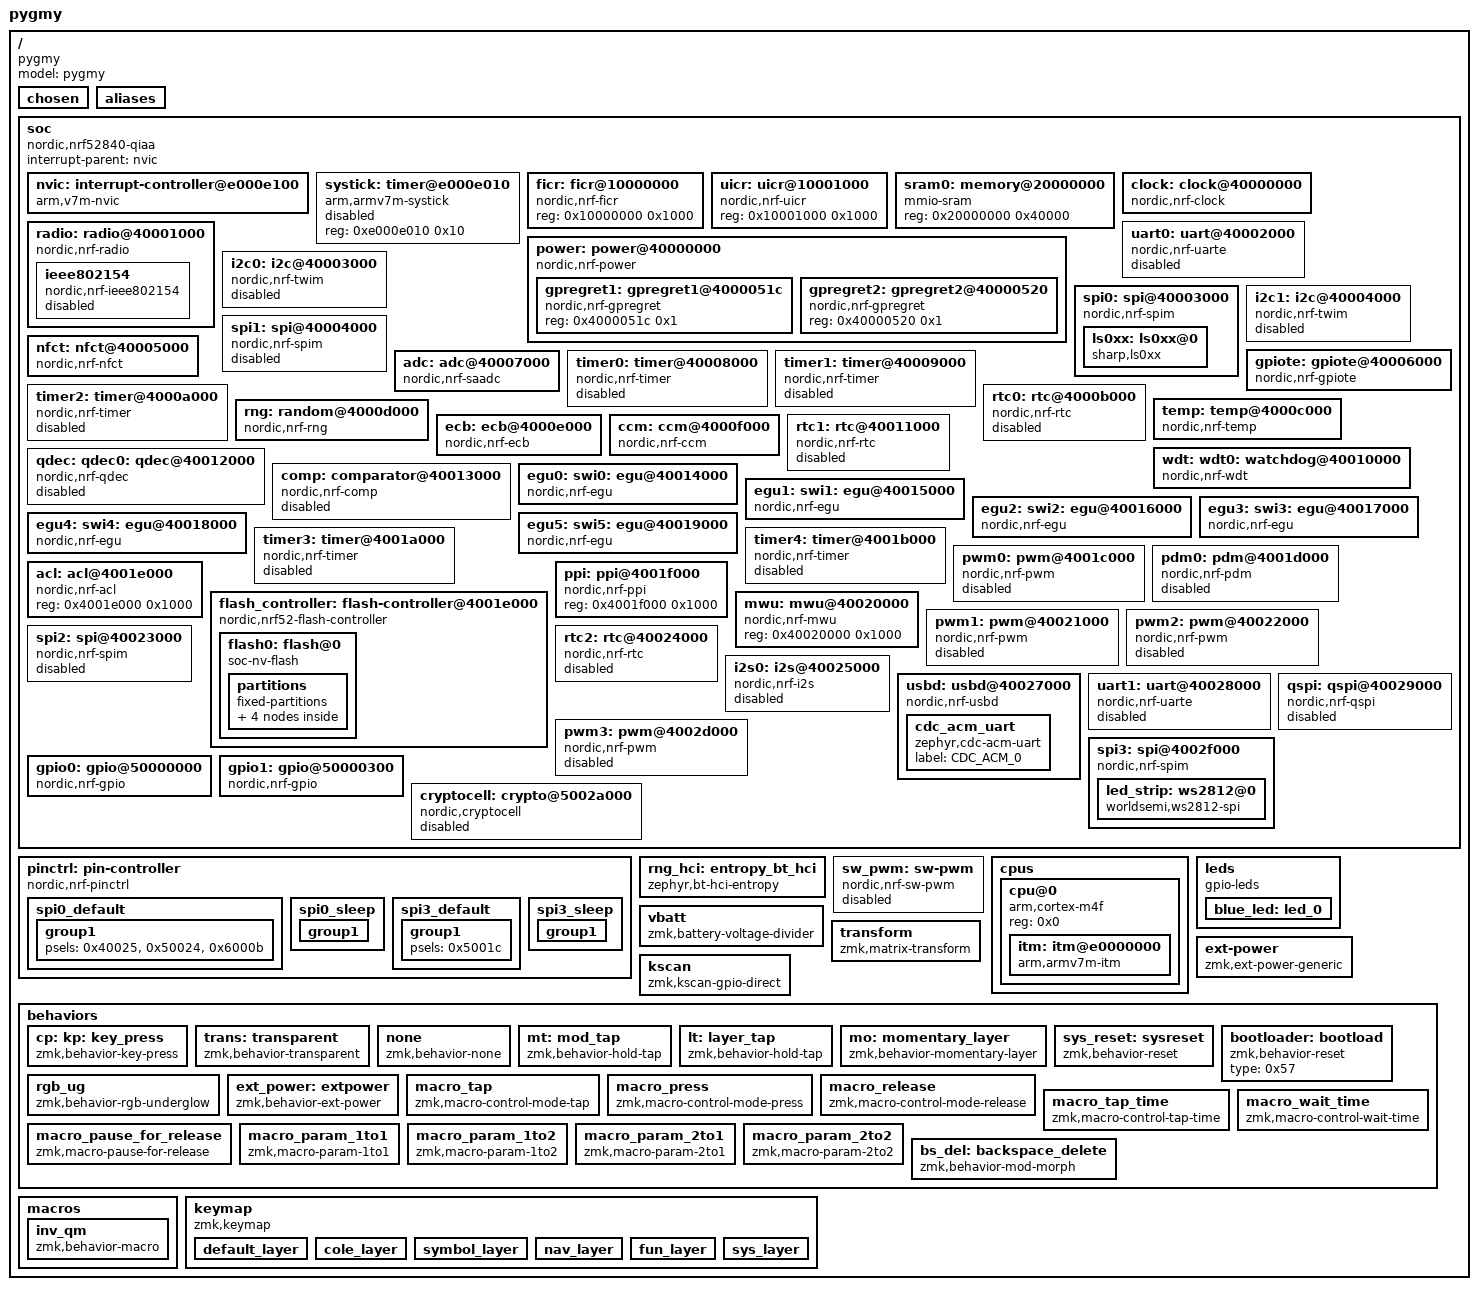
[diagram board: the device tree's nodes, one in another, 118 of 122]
/dts-v1/;

/ {
	#address-cells = < 0x1 >;
	#size-cells = < 0x1 >;
	model = "pygmy";
	compatible = "pygmy";
	chosen {
		zephyr,entropy = &rng;
		zephyr,flash-controller = &flash_controller;
		zephyr,code-partition = &code_partition;
		zephyr,sram = &sram0;
		zephyr,flash = &flash0;
		zephyr,display = &ls0xx;
		zmk,kscan = &kscan;
		zmk,matrix_transform = &transform;
		zmk,battery = &vbatt;
		zephyr,console = &cdc_acm_uart;
		zmk,underglow = &led_strip;
	};
	aliases {
	};
	soc {
		#address-cells = < 0x1 >;
		#size-cells = < 0x1 >;
		compatible = "nordic,nrf52840-qiaa", "nordic,nrf52840", "nordic,nrf52", "simple-bus";
		interrupt-parent = < &nvic >;
		ranges;
		nvic: interrupt-controller@e000e100 {
			#address-cells = < 0x1 >;
			compatible = "arm,v7m-nvic";
			reg = < 0xe000e100 0xc00 >;
			interrupt-controller;
			#interrupt-cells = < 0x2 >;
			arm,num-irq-priority-bits = < 0x3 >;
			phandle = < 0x1 >;
		};
		systick: timer@e000e010 {
			compatible = "arm,armv7m-systick";
			reg = < 0xe000e010 0x10 >;
			status = "disabled";
		};
		ficr: ficr@10000000 {
			compatible = "nordic,nrf-ficr";
			reg = < 0x10000000 0x1000 >;
			status = "okay";
		};
		uicr: uicr@10001000 {
			compatible = "nordic,nrf-uicr";
			reg = < 0x10001000 0x1000 >;
			status = "okay";
		};
		sram0: memory@20000000 {
			compatible = "mmio-sram";
			reg = < 0x20000000 0x40000 >;
		};
		clock: clock@40000000 {
			compatible = "nordic,nrf-clock";
			reg = < 0x40000000 0x1000 >;
			interrupts = < 0x0 0x1 >;
			status = "okay";
		};
		power: power@40000000 {
			compatible = "nordic,nrf-power";
			reg = < 0x40000000 0x1000 >;
			interrupts = < 0x0 0x1 >;
			status = "okay";
			#address-cells = < 0x1 >;
			#size-cells = < 0x1 >;
			gpregret1: gpregret1@4000051c {
				#address-cells = < 0x1 >;
				#size-cells = < 0x1 >;
				compatible = "nordic,nrf-gpregret";
				reg = < 0x4000051c 0x1 >;
				status = "okay";
			};
			gpregret2: gpregret2@40000520 {
				#address-cells = < 0x1 >;
				#size-cells = < 0x1 >;
				compatible = "nordic,nrf-gpregret";
				reg = < 0x40000520 0x1 >;
				status = "okay";
			};
		};
		radio: radio@40001000 {
			compatible = "nordic,nrf-radio";
			reg = < 0x40001000 0x1000 >;
			interrupts = < 0x1 0x1 >;
			status = "okay";
			ieee802154-supported;
			ble-2mbps-supported;
			ble-coded-phy-supported;
			tx-high-power-supported;
			ieee802154: ieee802154 {
				compatible = "nordic,nrf-ieee802154";
				status = "disabled";
			};
		};
		uart0: uart@40002000 {
			compatible = "nordic,nrf-uarte";
			reg = < 0x40002000 0x1000 >;
			interrupts = < 0x2 0x1 >;
			status = "disabled";
		};
		i2c0: i2c@40003000 {
			compatible = "nordic,nrf-twim";
			#address-cells = < 0x1 >;
			#size-cells = < 0x0 >;
			reg = < 0x40003000 0x1000 >;
			clock-frequency = < 0x186a0 >;
			interrupts = < 0x3 0x1 >;
			easydma-maxcnt-bits = < 0x10 >;
			status = "disabled";
		};
		spi0: spi@40003000 {
			compatible = "nordic,nrf-spim";
			#address-cells = < 0x1 >;
			#size-cells = < 0x0 >;
			reg = < 0x40003000 0x1000 >;
			interrupts = < 0x3 0x1 >;
			max-frequency = < 0x7a1200 >;
			easydma-maxcnt-bits = < 0x10 >;
			status = "okay";
			pinctrl-0 = < &spi0_default >;
			pinctrl-1 = < &spi0_default >;
			pinctrl-names = "default", "sleep";
			cs-gpios = < &gpio0 0x1e 0x0 >;
			ls0xx: ls0xx@0 {
				compatible = "sharp,ls0xx";
				spi-max-frequency = < 0x1e8480 >;
				reg = < 0x0 >;
				width = < 0x90 >;
				height = < 0xa8 >;
			};
		};
		i2c1: i2c@40004000 {
			compatible = "nordic,nrf-twim";
			#address-cells = < 0x1 >;
			#size-cells = < 0x0 >;
			reg = < 0x40004000 0x1000 >;
			clock-frequency = < 0x186a0 >;
			interrupts = < 0x4 0x1 >;
			easydma-maxcnt-bits = < 0x10 >;
			status = "disabled";
		};
		spi1: spi@40004000 {
			compatible = "nordic,nrf-spim";
			#address-cells = < 0x1 >;
			#size-cells = < 0x0 >;
			reg = < 0x40004000 0x1000 >;
			interrupts = < 0x4 0x1 >;
			max-frequency = < 0x7a1200 >;
			easydma-maxcnt-bits = < 0x10 >;
			status = "disabled";
		};
		nfct: nfct@40005000 {
			compatible = "nordic,nrf-nfct";
			reg = < 0x40005000 0x1000 >;
			interrupts = < 0x5 0x1 >;
			status = "okay";
		};
		gpiote: gpiote@40006000 {
			compatible = "nordic,nrf-gpiote";
			reg = < 0x40006000 0x1000 >;
			interrupts = < 0x6 0x5 >;
			status = "okay";
		};
		adc: adc@40007000 {
			compatible = "nordic,nrf-saadc";
			reg = < 0x40007000 0x1000 >;
			interrupts = < 0x7 0x1 >;
			status = "okay";
			#io-channel-cells = < 0x1 >;
			phandle = < 0x7 >;
		};
		timer0: timer@40008000 {
			compatible = "nordic,nrf-timer";
			status = "disabled";
			reg = < 0x40008000 0x1000 >;
			cc-num = < 0x4 >;
			max-bit-width = < 0x20 >;
			interrupts = < 0x8 0x1 >;
			prescaler = < 0x0 >;
		};
		timer1: timer@40009000 {
			compatible = "nordic,nrf-timer";
			status = "disabled";
			reg = < 0x40009000 0x1000 >;
			cc-num = < 0x4 >;
			max-bit-width = < 0x20 >;
			interrupts = < 0x9 0x1 >;
			prescaler = < 0x0 >;
			phandle = < 0x6 >;
		};
		timer2: timer@4000a000 {
			compatible = "nordic,nrf-timer";
			status = "disabled";
			reg = < 0x4000a000 0x1000 >;
			cc-num = < 0x4 >;
			max-bit-width = < 0x20 >;
			interrupts = < 0xa 0x1 >;
			prescaler = < 0x0 >;
		};
		rtc0: rtc@4000b000 {
			compatible = "nordic,nrf-rtc";
			reg = < 0x4000b000 0x1000 >;
			cc-num = < 0x3 >;
			interrupts = < 0xb 0x1 >;
			status = "disabled";
			clock-frequency = < 0x8000 >;
			prescaler = < 0x1 >;
		};
		temp: temp@4000c000 {
			compatible = "nordic,nrf-temp";
			reg = < 0x4000c000 0x1000 >;
			interrupts = < 0xc 0x1 >;
			status = "okay";
		};
		rng: random@4000d000 {
			compatible = "nordic,nrf-rng";
			reg = < 0x4000d000 0x1000 >;
			interrupts = < 0xd 0x1 >;
			status = "okay";
		};
		ecb: ecb@4000e000 {
			compatible = "nordic,nrf-ecb";
			reg = < 0x4000e000 0x1000 >;
			interrupts = < 0xe 0x1 >;
			status = "okay";
		};
		ccm: ccm@4000f000 {
			compatible = "nordic,nrf-ccm";
			reg = < 0x4000f000 0x1000 >;
			interrupts = < 0xf 0x1 >;
			length-field-length-8-bits;
			status = "okay";
		};
		wdt: wdt0: watchdog@40010000 {
			compatible = "nordic,nrf-wdt";
			reg = < 0x40010000 0x1000 >;
			interrupts = < 0x10 0x1 >;
			status = "okay";
		};
		rtc1: rtc@40011000 {
			compatible = "nordic,nrf-rtc";
			reg = < 0x40011000 0x1000 >;
			cc-num = < 0x4 >;
			interrupts = < 0x11 0x1 >;
			status = "disabled";
			clock-frequency = < 0x8000 >;
			prescaler = < 0x1 >;
		};
		qdec: qdec0: qdec@40012000 {
			compatible = "nordic,nrf-qdec";
			reg = < 0x40012000 0x1000 >;
			interrupts = < 0x12 0x1 >;
			status = "disabled";
		};
		comp: comparator@40013000 {
			compatible = "nordic,nrf-comp";
			reg = < 0x40013000 0x1000 >;
			interrupts = < 0x13 0x1 >;
			status = "disabled";
			#io-channel-cells = < 0x1 >;
		};
		egu0: swi0: egu@40014000 {
			compatible = "nordic,nrf-egu", "nordic,nrf-swi";
			reg = < 0x40014000 0x1000 >;
			interrupts = < 0x14 0x1 >;
			status = "okay";
		};
		egu1: swi1: egu@40015000 {
			compatible = "nordic,nrf-egu", "nordic,nrf-swi";
			reg = < 0x40015000 0x1000 >;
			interrupts = < 0x15 0x1 >;
			status = "okay";
		};
		egu2: swi2: egu@40016000 {
			compatible = "nordic,nrf-egu", "nordic,nrf-swi";
			reg = < 0x40016000 0x1000 >;
			interrupts = < 0x16 0x1 >;
			status = "okay";
		};
		egu3: swi3: egu@40017000 {
			compatible = "nordic,nrf-egu", "nordic,nrf-swi";
			reg = < 0x40017000 0x1000 >;
			interrupts = < 0x17 0x1 >;
			status = "okay";
		};
		egu4: swi4: egu@40018000 {
			compatible = "nordic,nrf-egu", "nordic,nrf-swi";
			reg = < 0x40018000 0x1000 >;
			interrupts = < 0x18 0x1 >;
			status = "okay";
		};
		egu5: swi5: egu@40019000 {
			compatible = "nordic,nrf-egu", "nordic,nrf-swi";
			reg = < 0x40019000 0x1000 >;
			interrupts = < 0x19 0x1 >;
			status = "okay";
		};
		timer3: timer@4001a000 {
			compatible = "nordic,nrf-timer";
			status = "disabled";
			reg = < 0x4001a000 0x1000 >;
			cc-num = < 0x6 >;
			max-bit-width = < 0x20 >;
			interrupts = < 0x1a 0x1 >;
			prescaler = < 0x0 >;
		};
		timer4: timer@4001b000 {
			compatible = "nordic,nrf-timer";
			status = "disabled";
			reg = < 0x4001b000 0x1000 >;
			cc-num = < 0x6 >;
			max-bit-width = < 0x20 >;
			interrupts = < 0x1b 0x1 >;
			prescaler = < 0x0 >;
		};
		pwm0: pwm@4001c000 {
			compatible = "nordic,nrf-pwm";
			reg = < 0x4001c000 0x1000 >;
			interrupts = < 0x1c 0x1 >;
			status = "disabled";
			#pwm-cells = < 0x3 >;
		};
		pdm0: pdm@4001d000 {
			compatible = "nordic,nrf-pdm";
			reg = < 0x4001d000 0x1000 >;
			interrupts = < 0x1d 0x1 >;
			status = "disabled";
		};
		acl: acl@4001e000 {
			compatible = "nordic,nrf-acl";
			reg = < 0x4001e000 0x1000 >;
			status = "okay";
		};
		flash_controller: flash-controller@4001e000 {
			compatible = "nordic,nrf52-flash-controller";
			reg = < 0x4001e000 0x1000 >;
			partial-erase;
			#address-cells = < 0x1 >;
			#size-cells = < 0x1 >;
			flash0: flash@0 {
				compatible = "soc-nv-flash";
				erase-block-size = < 0x1000 >;
				write-block-size = < 0x4 >;
				reg = < 0x0 0x100000 >;
				partitions {
					compatible = "fixed-partitions";
					#address-cells = < 0x1 >;
					#size-cells = < 0x1 >;
					sd_partition: partition@0 {
						reg = < 0x0 0x1000 >;
					};
					code_partition: partition@1000 {
						reg = < 0x1000 0xd3000 >;
					};
					storage_partition: partition@d4000 {
						reg = < 0xd4000 0x20000 >;
					};
					boot_partition: partition@f4000 {
						reg = < 0xf4000 0xc000 >;
					};
				};
			};
		};
		ppi: ppi@4001f000 {
			compatible = "nordic,nrf-ppi";
			reg = < 0x4001f000 0x1000 >;
			status = "okay";
		};
		mwu: mwu@40020000 {
			compatible = "nordic,nrf-mwu";
			reg = < 0x40020000 0x1000 >;
			status = "okay";
		};
		pwm1: pwm@40021000 {
			compatible = "nordic,nrf-pwm";
			reg = < 0x40021000 0x1000 >;
			interrupts = < 0x21 0x1 >;
			status = "disabled";
			#pwm-cells = < 0x3 >;
		};
		pwm2: pwm@40022000 {
			compatible = "nordic,nrf-pwm";
			reg = < 0x40022000 0x1000 >;
			interrupts = < 0x22 0x1 >;
			status = "disabled";
			#pwm-cells = < 0x3 >;
		};
		spi2: spi@40023000 {
			compatible = "nordic,nrf-spim";
			#address-cells = < 0x1 >;
			#size-cells = < 0x0 >;
			reg = < 0x40023000 0x1000 >;
			interrupts = < 0x23 0x1 >;
			max-frequency = < 0x7a1200 >;
			easydma-maxcnt-bits = < 0x10 >;
			status = "disabled";
		};
		rtc2: rtc@40024000 {
			compatible = "nordic,nrf-rtc";
			reg = < 0x40024000 0x1000 >;
			cc-num = < 0x4 >;
			interrupts = < 0x24 0x1 >;
			status = "disabled";
			clock-frequency = < 0x8000 >;
			prescaler = < 0x1 >;
		};
		i2s0: i2s@40025000 {
			compatible = "nordic,nrf-i2s";
			#address-cells = < 0x1 >;
			#size-cells = < 0x0 >;
			reg = < 0x40025000 0x1000 >;
			interrupts = < 0x25 0x1 >;
			status = "disabled";
		};
		usbd: usbd@40027000 {
			compatible = "nordic,nrf-usbd";
			reg = < 0x40027000 0x1000 >;
			interrupts = < 0x27 0x1 >;
			num-bidir-endpoints = < 0x1 >;
			num-in-endpoints = < 0x7 >;
			num-out-endpoints = < 0x7 >;
			num-isoin-endpoints = < 0x1 >;
			num-isoout-endpoints = < 0x1 >;
			status = "okay";
			cdc_acm_uart: cdc_acm_uart {
				compatible = "zephyr,cdc-acm-uart";
				label = "CDC_ACM_0";
			};
		};
		uart1: uart@40028000 {
			compatible = "nordic,nrf-uarte";
			reg = < 0x40028000 0x1000 >;
			interrupts = < 0x28 0x1 >;
			status = "disabled";
		};
		qspi: qspi@40029000 {
			compatible = "nordic,nrf-qspi";
			#address-cells = < 0x1 >;
			#size-cells = < 0x0 >;
			reg = < 0x40029000 0x1000 >, < 0x12000000 0x8000000 >;
			reg-names = "qspi", "qspi_mm";
			interrupts = < 0x29 0x1 >;
			status = "disabled";
		};
		pwm3: pwm@4002d000 {
			compatible = "nordic,nrf-pwm";
			reg = < 0x4002d000 0x1000 >;
			interrupts = < 0x2d 0x1 >;
			status = "disabled";
			#pwm-cells = < 0x3 >;
		};
		spi3: spi@4002f000 {
			compatible = "nordic,nrf-spim";
			#address-cells = < 0x1 >;
			#size-cells = < 0x0 >;
			reg = < 0x4002f000 0x1000 >;
			interrupts = < 0x2f 0x1 >;
			max-frequency = < 0x1e84800 >;
			easydma-maxcnt-bits = < 0x10 >;
			rx-delay-supported;
			rx-delay = < 0x2 >;
			status = "okay";
			pinctrl-0 = < &spi3_default >;
			pinctrl-1 = < &spi3_sleep >;
			pinctrl-names = "default", "sleep";
			led_strip: ws2812@0 {
				compatible = "worldsemi,ws2812-spi";
				reg = < 0x0 >;
				spi-max-frequency = < 0x3d0900 >;
				chain-length = < 0x11 >;
				spi-one-frame = < 0x70 >;
				spi-zero-frame = < 0x40 >;
				color-mapping = < 0x0 0x64 0x0 >;
			};
		};
		gpio0: gpio@50000000 {
			compatible = "nordic,nrf-gpio";
			gpio-controller;
			reg = < 0x50000000 0x200 0x50000500 0x300 >;
			#gpio-cells = < 0x2 >;
			status = "okay";
			port = < 0x0 >;
			phandle = < 0x3 >;
		};
		gpio1: gpio@50000300 {
			compatible = "nordic,nrf-gpio";
			gpio-controller;
			reg = < 0x50000300 0x200 0x50000800 0x300 >;
			#gpio-cells = < 0x2 >;
			ngpios = < 0x10 >;
			status = "okay";
			port = < 0x1 >;
			phandle = < 0x8 >;
		};
		cryptocell: crypto@5002a000 {
			compatible = "nordic,cryptocell", "arm,cryptocell-310";
			reg = < 0x5002a000 0x1000 >, < 0x5002b000 0x1000 >;
			reg-names = "wrapper", "core";
			interrupts = < 0x2a 0x1 >;
			status = "disabled";
		};
	};
	pinctrl: pin-controller {
		compatible = "nordic,nrf-pinctrl";
		spi0_default: spi0_default {
			phandle = < 0x2 >;
			group1 {
				psels = < 0x40025 >, < 0x50024 >, < 0x6000b >;
			};
		};
		spi0_sleep: spi0_sleep {
			group1 {
				psels = < 0x40025 >, < 0x50024 >, < 0x6000b >;
				low-power-enable;
			};
		};
		spi3_default: spi3_default {
			phandle = < 0x4 >;
			group1 {
				psels = < 0x5001c >;
			};
		};
		spi3_sleep: spi3_sleep {
			phandle = < 0x5 >;
			group1 {
				psels = < 0x5001c >;
				low-power-enable;
			};
		};
	};
	rng_hci: entropy_bt_hci {
		compatible = "zephyr,bt-hci-entropy";
		status = "okay";
	};
	sw_pwm: sw-pwm {
		compatible = "nordic,nrf-sw-pwm";
		status = "disabled";
		generator = < &timer1 >;
		clock-prescaler = < 0x0 >;
		#pwm-cells = < 0x3 >;
	};
	cpus {
		#address-cells = < 0x1 >;
		#size-cells = < 0x0 >;
		cpu@0 {
			device_type = "cpu";
			compatible = "arm,cortex-m4f";
			reg = < 0x0 >;
			#address-cells = < 0x1 >;
			#size-cells = < 0x1 >;
			itm: itm@e0000000 {
				compatible = "arm,armv7m-itm";
				reg = < 0xe0000000 0x1000 >;
				swo-ref-frequency = < 0x1e84800 >;
			};
		};
	};
	leds {
		compatible = "gpio-leds";
		blue_led: led_0 {
			gpios = < &gpio0 0x16 0x0 >;
			label = "Blue LED";
		};
	};
	vbatt: vbatt {
		compatible = "zmk,battery-voltage-divider";
		io-channels = < &adc 0x7 >;
		output-ohms = < 0x1e8480 >;
		full-ohms = < 0x2ad0f0 >;
	};
	ext-power {
		compatible = "zmk,ext-power-generic";
		label = "EXT_POWER";
		control-gpios = < &gpio0 0x5 0x0 >;
		init-delay-ms = < 0x32 >;
	};
	transform: transform {
		compatible = "zmk,matrix-transform";
		columns = < 0xa >;
		rows = < 0x4 >;
		map = < 0x0 0x1 0x2 0x3 0x4 0x15 0x14 0x13 0x12 0x11 0x5 0x6 0x7 0x8 0x9 0x1a 0x19 0x18 0x17 0x16 0xa 0xb 0xc 0xd 0xe 0x1f 0x1e 0x1d 0x1c 0x1b 0xf 0x10 0x21 0x20 >;
		col-offset = < 0x11 >;
	};
	kscan: kscan {
		compatible = "zmk,kscan-gpio-direct";
		label = "KSCAN";
		input-gpios = < &gpio0 0xc 0x11 >, < &gpio0 0x10 0x11 >, < &gpio0 0xd 0x11 >, < &gpio0 0xe 0x11 >, < &gpio1 0x0 0x11 >, < &gpio1 0x9 0x11 >, < &gpio0 0x17 0x11 >, < &gpio0 0x15 0x11 >, < &gpio0 0xf 0x11 >, < &gpio1 0x3 0x11 >, < &gpio0 0x1a 0x11 >, < &gpio0 0x7 0x11 >, < &gpio0 0x13 0x11 >, < &gpio0 0x11 0x11 >, < &gpio1 0x1 0x11 >, < &gpio0 0x9 0x11 >, < &gpio0 0xa 0x11 >;
	};
	behaviors {
		cp: kp: key_press {
			compatible = "zmk,behavior-key-press";
			#binding-cells = < 0x1 >;
			phandle = < 0x9 >;
		};
		trans: transparent {
			compatible = "zmk,behavior-transparent";
			#binding-cells = < 0x0 >;
			phandle = < 0x14 >;
		};
		none: none {
			compatible = "zmk,behavior-none";
			#binding-cells = < 0x0 >;
			phandle = < 0x13 >;
		};
		mt: mod_tap {
			compatible = "zmk,behavior-hold-tap";
			#binding-cells = < 0x2 >;
			flavor = "hold-preferred";
			tapping-term-ms = < 0xc8 >;
			bindings = < &kp >, < &kp >;
			phandle = < 0xf >;
		};
		lt: layer_tap {
			compatible = "zmk,behavior-hold-tap";
			#binding-cells = < 0x2 >;
			flavor = "balanced";
			tapping-term-ms = < 0xc8 >;
			bindings = < &mo >, < &kp >;
			phandle = < 0x10 >;
		};
		mo: momentary_layer {
			compatible = "zmk,behavior-momentary-layer";
			#binding-cells = < 0x1 >;
			phandle = < 0xa >;
		};
		sys_reset: sysreset {
			compatible = "zmk,behavior-reset";
			#binding-cells = < 0x0 >;
		};
		bootloader: bootload {
			compatible = "zmk,behavior-reset";
			type = < 0x57 >;
			#binding-cells = < 0x0 >;
		};
		rgb_ug: rgb_ug {
			compatible = "zmk,behavior-rgb-underglow";
			#binding-cells = < 0x2 >;
			phandle = < 0xe >;
		};
		ext_power: extpower {
			compatible = "zmk,behavior-ext-power";
			#binding-cells = < 0x1 >;
		};
		macro_tap: macro_tap {
			compatible = "zmk,macro-control-mode-tap";
			#binding-cells = < 0x0 >;
			phandle = < 0xc >;
		};
		macro_press: macro_press {
			compatible = "zmk,macro-control-mode-press";
			#binding-cells = < 0x0 >;
			phandle = < 0xb >;
		};
		macro_release: macro_release {
			compatible = "zmk,macro-control-mode-release";
			#binding-cells = < 0x0 >;
			phandle = < 0xd >;
		};
		macro_tap_time: macro_tap_time {
			compatible = "zmk,macro-control-tap-time";
			#binding-cells = < 0x1 >;
		};
		macro_wait_time: macro_wait_time {
			compatible = "zmk,macro-control-wait-time";
			#binding-cells = < 0x1 >;
		};
		macro_pause_for_release: macro_pause_for_release {
			compatible = "zmk,macro-pause-for-release";
			#binding-cells = < 0x0 >;
		};
		macro_param_1to1: macro_param_1to1 {
			compatible = "zmk,macro-param-1to1";
			#binding-cells = < 0x0 >;
		};
		macro_param_1to2: macro_param_1to2 {
			compatible = "zmk,macro-param-1to2";
			#binding-cells = < 0x0 >;
		};
		macro_param_2to1: macro_param_2to1 {
			compatible = "zmk,macro-param-2to1";
			#binding-cells = < 0x0 >;
		};
		macro_param_2to2: macro_param_2to2 {
			compatible = "zmk,macro-param-2to2";
			#binding-cells = < 0x0 >;
		};
		bs_del: backspace_delete {
			compatible = "zmk,behavior-mod-morph";
			#binding-cells = < 0x0 >;
			bindings = < &kp 0x7002a >, < &kp 0x7004c >;
			mods = < 0x22 >;
			keep-mods = < 0x20 >;
			phandle = < 0x11 >;
		};
	};
	macros {
		inv_qm: inv_qm {
			compatible = "zmk,behavior-macro";
			#binding-cells = < 0x0 >;
			wait-ms = < 0xa >;
			tap-ms = < 0xa >;
			bindings = < &macro_press &kp 0x700e2 >, < &macro_tap &kp 0x70059 &kp 0x7005e &kp 0x70060 >, < &macro_release &kp 0x700e2 >;
			phandle = < 0x12 >;
		};
	};
	keymap {
		compatible = "zmk,keymap";
		default_layer {
			display-name = "DEF";
			bindings = < &kp 0x70014 &kp 0x7001a &kp 0x70008 &kp 0x70015 &kp 0x70017 &kp 0x7001c &rgb_ug 0x0 0x0 &kp 0x7000c &kp 0x70012 &kp 0x70013 &mt 0x700e3 0x70004 &mt 0x700e2 0x70016 &mt 0x700e0 0x70007 &mt 0x700e1 0x70009 &kp 0x7000a &kp 0x7000b &mt 0x700e5 0x7000d &mt 0x700e0 0x7000e &mt 0x700e2 0x7000f &mt 0x700e3 0x70033 &kp 0x7001d &kp 0x7001b &kp 0x70006 &kp 0x70019 &kp 0x70005 &kp 0x70011 &kp 0x70010 &kp 0x70036 &kp 0x70037 &kp 0x70038 &mt 0x700e0 0x70029 &lt 0x3 0x7002c &lt 0x2 0x70028 &bs_del >;
		};
		cole_layer {
			bindings = < &kp 0x70014 &kp 0x7001a &kp 0x70009 &kp 0x70013 &kp 0x70005 &kp 0x7000d &kp 0x7000f &kp 0x70018 &kp 0x7001c &kp 0x70033 &mt 0x700e3 0x70004 &mt 0x700e2 0x70015 &mt 0x700e0 0x70016 &mt 0x700e1 0x70017 &kp 0x7000a &kp 0x70010 &mt 0x700e5 0x70011 &mt 0x700e0 0x70008 &mt 0x700e2 0x7000c &mt 0x700e3 0x70012 &kp 0x7001d &kp 0x7001b &kp 0x70006 &kp 0x70007 &kp 0x70019 &kp 0x7000e &kp 0x7000b &kp 0x70036 &kp 0x70037 &kp 0x70038 &mt 0x700e0 0x70029 &lt 0x3 0x7002c &lt 0x2 0x70028 &bs_del >;
		};
		symbol_layer {
			display-name = "SYM";
			bindings = < &kp 0x207001e &kp 0x207001f &kp 0x2070020 &kp 0x2070021 &kp 0x2070022 &kp 0x70038 &kp 0x70024 &kp 0x70025 &kp 0x70026 &kp 0x70036 &kp 0x207002e &kp 0x7002e &kp 0x207002d &kp 0x7002d &kp 0x2070023 &kp 0x70027 &kp 0x70021 &kp 0x70022 &kp 0x70023 &kp 0x70037 &mo 0x4 &inv_qm &kp 0x2070025 &kp 0x2070024 &none &kp 0x70033 &kp 0x7001e &kp 0x7001f &kp 0x70020 &kp 0x70038 &kp 0x7002a &trans &trans &bs_del >;
		};
		nav_layer {
			display-name = "NAV";
			bindings = < &kp 0x407003d &kp 0x307002b &kp 0x107002b &kp 0x107003d &kp 0xc00e9 &kp 0x70049 &kp 0x7004e &kp 0x70052 &kp 0x7004b &kp 0xc0192 &kp 0x700e0 &kp 0x700e3 &kp 0x700e2 &mt 0x700e1 0x7002b &kp 0xc00ea &kp 0x7004a &kp 0x70050 &kp 0x70051 &kp 0x7004f &kp 0x7004d &none &none &none &kp 0x2070049 &kp 0xc00cd &none &kp 0x7004c &kp 0xc00b6 &kp 0xc00b5 &none &none &trans &trans &kp 0x7002c >;
		};
		fun_layer {
			display-name = "FUN";
			bindings = < &kp 0x407003d &kp 0x307002b &kp 0x107002b &kp 0x107003d &kp 0xc00e9 &kp 0x70049 &kp 0x7004e &kp 0x70052 &kp 0x7004b &kp 0xc0192 &kp 0x700e0 &kp 0x700e3 &kp 0x700e2 &mt 0x700e1 0x7002b &kp 0xc00ea &kp 0x7004a &kp 0x70050 &kp 0x70051 &kp 0x7004f &kp 0x7004d &rgb_ug &mo 0x0 &none &kp 0x2070049 &kp 0xc00cd &none &kp 0x7004c &kp 0xc00b6 &kp 0xc00b5 &none &none &trans &trans &kp 0x7002c >;
		};
		sys_layer {
			display-name = "SYS";
			bindings = < &kp 0x407003d &kp 0x307002b &kp 0x107002b &kp 0x107003d &kp 0xc00e9 &kp 0x70049 &kp 0x7004e &kp 0x70052 &kp 0x7004b &kp 0xc0192 &kp 0x700e0 &kp 0x700e3 &kp 0x700e2 &mt 0x700e1 0x7002b &kp 0xc00ea &kp 0x7004a &kp 0x70050 &kp 0x70051 &kp 0x7004f &kp 0x7004d &none &none &none &kp 0x2070049 &kp 0xc00cd &none &kp 0x7004c &kp 0xc00b6 &kp 0xc00b5 &none &none &trans &trans &kp 0x7002c >;
		};
	};
};
